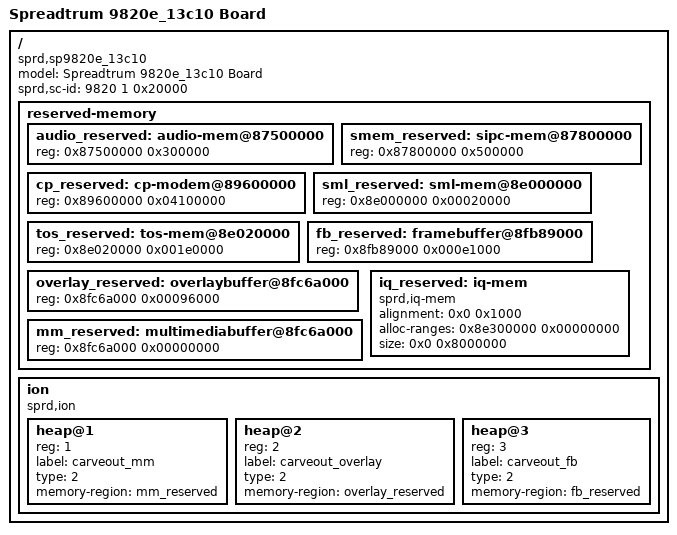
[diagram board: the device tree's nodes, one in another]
/*
 * Spreadtrum SP9860g board DTS file
 *
 * Copyright (C) 2016, Spreadtrum Communications Inc.
 *
 * This file is licensed under a dual GPLv2 or X11 license.
 */

/dts-v1/;

/ {
	model = "Spreadtrum 9820e_13c10 Board";

	compatible = "sprd,sp9820e_13c10";

	sprd,sc-id = <9820 1 0x20000>;

	reserved-memory {
		#address-cells = <1>;
		#size-cells = <1>;
		ranges;

		audio_reserved: audio-mem@87500000 {
			reg = <0x87500000 0x300000>;
		};

		smem_reserved: sipc-mem@87800000 {
			reg = <0x87800000 0x500000>;
		};

		cp_reserved: cp-modem@89600000 {
			reg = <0x89600000 0x04100000>;
		};

		/* must be 4K aligned */
		sml_reserved: sml-mem@8e000000{
                        reg = <0x8e000000 0x00020000>;
                };

                tos_reserved: tos-mem@8e020000{
                        reg = <0x8e020000 0x001e0000>;
                };

		fb_reserved: framebuffer@8fb89000{
			reg = <0x8fb89000 0x000e1000>;
		};

		overlay_reserved: overlaybuffer@8fc6a000{
			reg = <0x8fc6a000 0x00096000>;
		};

		/* For cma 4M align, enlarge its size from 0xd840000 to 0xd8d0000 */
		mm_reserved: multimediabuffer@8fc6a000{
			reg = <0x8fc6a000 0x00000000>;
		};

		iq_reserved: iq-mem{
			compatible = "sprd,iq-mem";
			alignment = <0x0 0x1000>;
			alloc-ranges = <0x8e300000 0x00000000>;
			size = <0x0 0x8000000>;
		};
	};


	ion {
		compatible = "sprd,ion";
		#address-cells = <1>;
		#size-cells = <0>;

		heap@1 {
			reg = <1>;
			label = "carveout_mm";
			type = <2>;
			memory-region = <&mm_reserved>;
		};

		heap@2 {
			reg = <2>;
			label = "carveout_overlay";
			type = <2>;
			memory-region = <&overlay_reserved>;
		};

		heap@3 {
			reg = <3>;
			label = "carveout_fb";
			type = <2>;
			memory-region = <&fb_reserved>;
		};
	};
};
